# CC26x0 register map
File version: 2.3
CPU: CM3 r2p1, little endian, no MPU, no FPU, 3 interrupt priority bits
Registers are 32-bit, read-write, reset 0x0 unless marked. A register's access mark holds for its fields unless they carry their own. Offsets are from the block's base; [hi:lo] are bit positions; {n}, {i} and the like mark numbered series; 'fields as' and 'values as' point back to an identical list.

## IOC — IO Controller (IOC) - configures all the DIOs and resides in the MCU domain.
Base 0x40081000
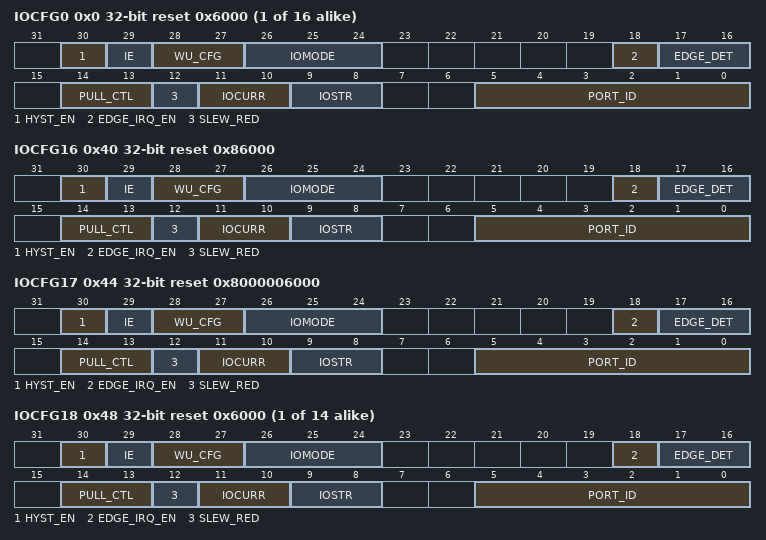
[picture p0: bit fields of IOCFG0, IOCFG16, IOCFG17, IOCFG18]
{0x0+4i} IOCFG{i} reset 0x6000 (i=0..15) — Configuration of DIO{i}
  [30] HYST_EN, [29] IE, [28:27] WU_CFG, [26:24] IOMODE, [18] EDGE_IRQ_EN, [17:16] EDGE_DET, [14:13] PULL_CTL, [12] SLEW_RED, [11:10] IOCURR, [9:8] IOSTR, [5:0] PORT_ID
0x40 IOCFG16 reset 0x86000 — Configuration of DIO16
  fields as IOCFG0
0x44 IOCFG17 reset 0x8000006000 — Configuration of DIO17
  fields as IOCFG0
{0x0+4i} IOCFG{i} reset 0x6000 (i=18..31) — Configuration of DIO{i}
  fields as IOCFG0

## RFC_DBELL — RF Core Doorbell
Base 0x40041000
0x00 CMDR — Doorbell Command Register
  [31:0] CMD
0x04 CMDSTA ro — Doorbell Command Status Register
  [31:0] STAT
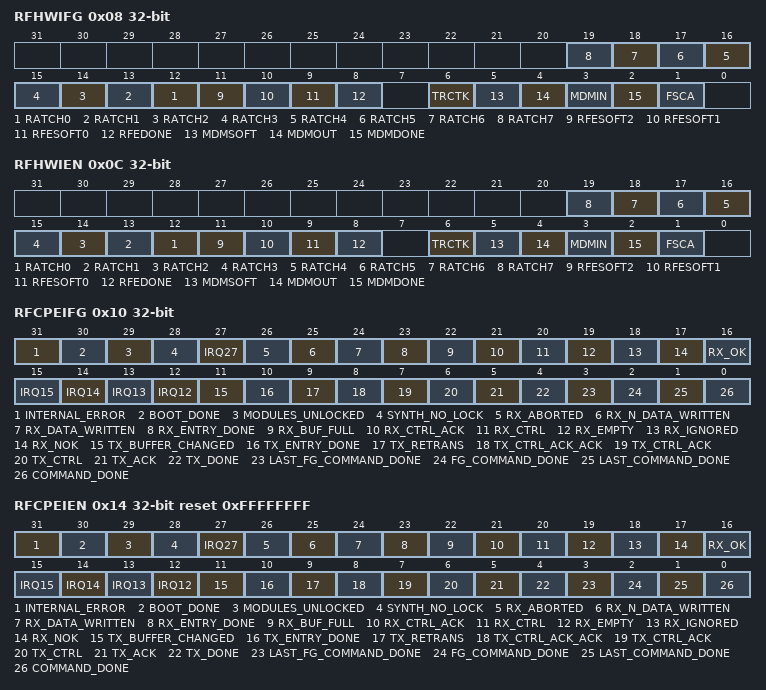
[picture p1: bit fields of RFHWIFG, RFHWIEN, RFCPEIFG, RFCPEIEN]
0x08 RFHWIFG — Interrupt Flags From RF Hardware Modules
  [n+12] RATCH{n} (n=0..7), [11] RFESOFT2, [10] RFESOFT1, [9] RFESOFT0, [8] RFEDONE, [6] TRCTK, [5] MDMSOFT, [4] MDMOUT, [3] MDMIN, [2] MDMDONE, [1] FSCA
0x0C RFHWIEN — Interrupt Enable For RF Hardware Modules
  fields as RFHWIFG
0x10 RFCPEIFG — Interrupt Flags For Command and Packet Engine Generated Interrupts
  [31] INTERNAL_ERROR, [30] BOOT_DONE, [29] MODULES_UNLOCKED, [28] SYNTH_NO_LOCK, [27] IRQ27, [26] RX_ABORTED, [25] RX_N_DATA_WRITTEN, [24] RX_DATA_WRITTEN, [23] RX_ENTRY_DONE, [22] RX_BUF_FULL, [21] RX_CTRL_ACK, [20] RX_CTRL, [19] RX_EMPTY, [18] RX_IGNORED, [17] RX_NOK, [16] RX_OK, [n] IRQ{n} (n=12..15), [11] TX_BUFFER_CHANGED, [10] TX_ENTRY_DONE, [9] TX_RETRANS, [8] TX_CTRL_ACK_ACK, [7] TX_CTRL_ACK, [6] TX_CTRL, [5] TX_ACK, [4] TX_DONE, [3] LAST_FG_COMMAND_DONE, [2] FG_COMMAND_DONE, [1] LAST_COMMAND_DONE, [0] COMMAND_DONE
0x14 RFCPEIEN reset 0xFFFFFFFF — Interrupt Enable For Command and Packet Engine Generated Interrupts
  fields as RFCPEIFG
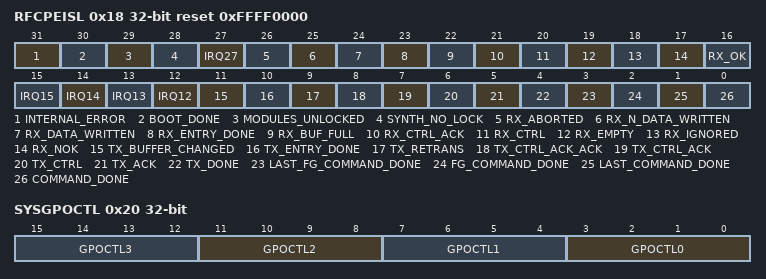
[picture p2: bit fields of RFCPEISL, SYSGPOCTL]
0x18 RFCPEISL reset 0xFFFF0000 — Interrupt Vector Selection For Command and Packet Engine Generated Interrupts
  fields as RFCPEIFG
0x1C RFACKIFG — Doorbell Command Acknowledgement Interrupt Flag
  [0] ACKFLAG
0x20 SYSGPOCTL — RF Core General Purpose Output Control
  [4n+3:4n] GPOCTL{n} (n=0..3)

## RFC_PWR — RF Core Power Management
Base 0x40040000
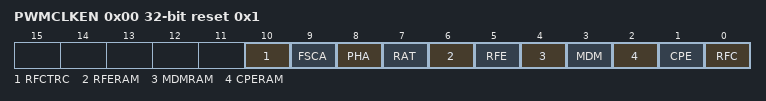
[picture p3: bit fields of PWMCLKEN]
0x00 PWMCLKEN reset 0x1 — RF Core Power Management and Clock Enable
  [10] RFCTRC, [9] FSCA, [8] PHA, [7] RAT, [6] RFERAM, [5] RFE, [4] MDMRAM, [3] MDM, [2] CPERAM, [1] CPE, [0] RFC

## RFC_RAT — RF Core Radio Timer
Base 0x40043000
0x04 RATCNT — Radio Timer Counter Value
  [31:0] CNT
{0x80+4i} RATCH{i}VAL (i=0..7) — Timer Channel {i} Capture/Compare Register
  [31:0] VAL

## SMPH — MCU Semaphore Module This module provides 32 binary semaphores. The state of a binary semaphore is either taken or available. A semaphore does not implement any ownership attribute. Still, a semaphore can be used to handle mutual exclusion scenarios.
Base 0x40084000
{0x0+4i} SMPH{i} reset 0x1 (i=0..31) — MCU SEMAPHORE {i}
  [0] STAT read-clears
{0x800+4i} PEEK{i} ro reset 0x1 (i=0..31) — MCU SEMAPHORE {i} ALIAS
  [0] STAT

## SSI0 — Synchronous Serial Interface with master and slave capabilities
Base 0x40000000
Same registers: SSI1 0x40008000
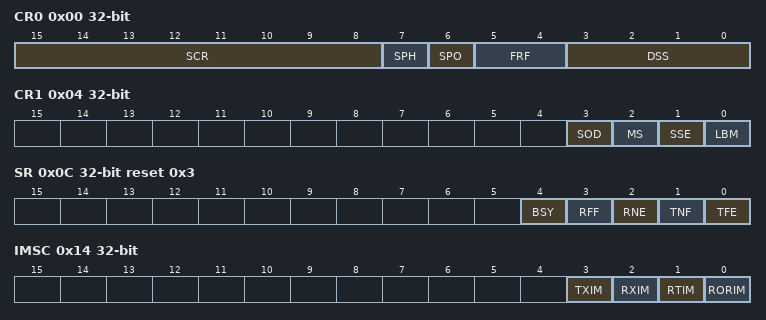
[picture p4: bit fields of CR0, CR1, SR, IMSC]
0x00 CR0 — Control 0
  [15:8] SCR, [7] SPH, [6] SPO, [5:4] FRF, [3:0] DSS
0x04 CR1 — Control 1
  [3] SOD, [2] MS, [1] SSE, [0] LBM
0x08 DR — Data 16-bits wide data register: When read, the entry in the receive FIFO, pointed to by the current FIFO read pointer, is accessed. As data values are removed by the receive logic from the incoming data frame, they are placed into the entry in the receive FIFO, pointed to by the current FIFO write pointer. When written, the entry in the transmit FIFO, pointed to by the write pointer, is written to. Data values are removed from the transmit FIFO one value at a time by the transmit logic. It is loaded into the transmit serial shifter, then serially shifted out onto the TXD output pin at the programmed bit rate. When a data size of less than 16 bits is selected, the user must right-justify data written to the transmit FIFO. The transmit logic ignores the unused bits. Received data less than 16 bits is automatically right-justified in the receive buffer.
  [15:0] DATA
0x0C SR ro reset 0x3 — Status
  [4] BSY, [3] RFF, [2] RNE, [1] TNF, [0] TFE
0x10 CPSR — Clock Prescale
  [7:0] CPSDVSR
0x14 IMSC — Interrupt Mask Set and Clear
  [3] TXIM, [2] RXIM, [1] RTIM, [0] RORIM
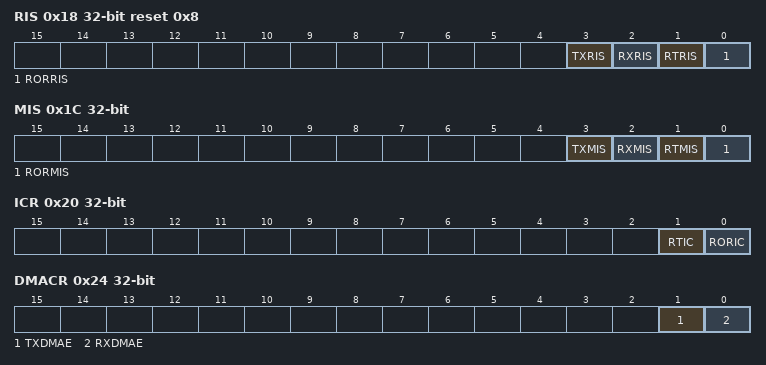
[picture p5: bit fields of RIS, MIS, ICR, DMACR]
0x18 RIS ro reset 0x8 — Raw Interrupt Status
  [3] TXRIS, [2] RXRIS, [1] RTRIS, [0] RORRIS
0x1C MIS ro — Masked Interrupt Status
  [3] TXMIS, [2] RXMIS, [1] RTMIS, [0] RORMIS
0x20 ICR wo — Interrupt Clear On a write of 1, the corresponding interrupt is cleared. A write of 0 has no effect.
  [1] RTIC, [0] RORIC
0x24 DMACR — DMA Control
  [1] TXDMAE, [0] RXDMAE
